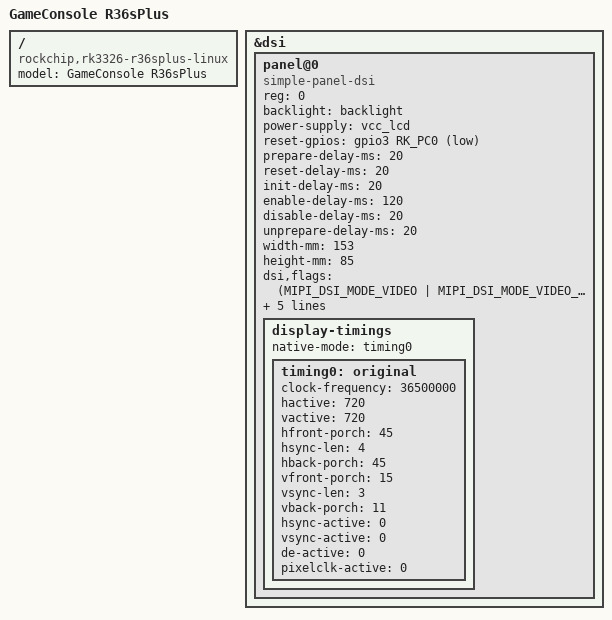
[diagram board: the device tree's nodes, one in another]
// SPDX-License-Identifier: (GPL-2.0+ OR MIT)
/*
* Copyright (c) 2026 kk&lcdyk
*
* GameConsole R36sPlus
*
*/

/dts-v1/;
#include "rk3326-r36s-panel0-linux.dts"

/ {
	model = "GameConsole R36sPlus";
	compatible = "rockchip,rk3326-r36splus-linux", "rockchip,rk3326";

};

&dsi {
	status = "okay";
	
	panel@0 {
		compatible = "simple-panel-dsi";
		reg = <0>;
		/* pwm1 backlight */
		backlight = <&backlight>;
		/* RK817 LDO8 */
		power-supply = <&vcc_lcd>;
		/* Rev 0.2 LCD reset gpio GPIO3.C0 */
		reset-gpios = <&gpio3 RK_PC0 GPIO_ACTIVE_LOW>;
		prepare-delay-ms = <20>;
		reset-delay-ms = <20>;
		init-delay-ms = <20>;
		enable-delay-ms = <120>;
		disable-delay-ms = <20>;
		unprepare-delay-ms = <20>;
		width-mm = <153>;
		height-mm = <85>;
		dsi,flags  = <(MIPI_DSI_MODE_VIDEO |
		MIPI_DSI_MODE_VIDEO_BURST |
		MIPI_DSI_MODE_LPM |
		MIPI_DSI_MODE_EOT_PACKET)>;
		dsi,format = <MIPI_DSI_FMT_RGB888>;
		dsi,lanes = <4>;
		panel-init-sequence = [05 fa 01 11 39 00 04 b9 f1 12 83 39 00 1c ba 33 81 05 f9 0e 0e 20 00 00 00 00 00 00 00 44 25 00 90 0a 00 00 01 4f 01 00 00 37 39 00 05 b8 25 22 f0 63 39 00 04 bf 02 11 00 39 00 0b b3 10 10 28 28 03 ff 00 00 00 00 39 00 0a c0 73 73 50 50 00 00 12 70 00 15 00 02 bc 46 15 00 02 cc 0b 15 00 02 b4 80 39 00 04 b2 3c 12 30 39 00 0f e3 07 07 0b 0b 03 0b 00 00 00 00 ff 00 c0 10 39 00 0d c1 36 00 32 32 77 f1 cc cc 77 77 33 33 39 00 03 b5 0a 0a 39 00 03 b6 88 88 39 00 40 e9 c8 10 0a 10 0f a1 80 12 31 23 47 86 a1 80 47 08 00 00 0d 00 00 00 00 00 0d 00 00 00 48 02 8b af 46 02 88 88 88 88 88 48 13 8b af 57 13 88 88 88 88 88 00 00 00 00 00 00 00 00 00 00 00 00 00 39 00 3e ea 96 12 01 01 01 78 02 00 00 00 00 00 4f 31 8b a8 31 75 88 88 88 88 88 4f 20 8b a8 20 64 88 88 88 88 88 23 00 00 01 02 00 00 00 00 00 00 00 00 00 00 00 00 00 00 00 40 a1 80 00 00 00 00 39 00 23 e0 00 0a 0f 29 3b 3f 42 39 06 0d 10 13 15 14 15 10 17 00 0a 0f 29 3b 3f 42 39 06 0d 10 13 15 14 15 10 17 05 32 01 29];
		panel-exit-sequence = <0x5140128 0x50a0110>;
		
		display-timings {
			native-mode = <&timing0>;
			
			// 36.50MHz / (720+45+4+45)×(720+15+3+11) = 814×749 = 59.87 Hz
			timing0: original {
				clock-frequency = <36500000>;
				hactive = <720>;
				vactive = <720>;
				hfront-porch = <45>;
				hsync-len = <4>;
				hback-porch = <45>;
				vfront-porch = <15>;
				vsync-len = <3>;
				vback-porch = <11>;
				hsync-active = <0>;
				vsync-active = <0>;
				de-active = <0>;
				pixelclk-active = <0>;
			};
		};
	};
};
